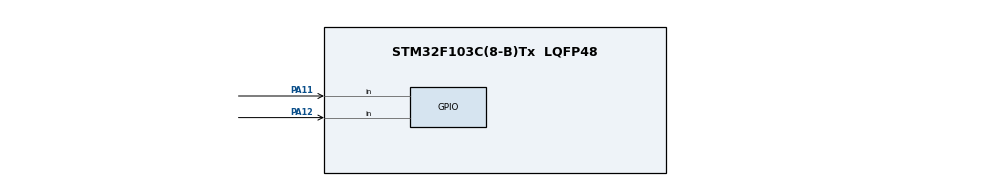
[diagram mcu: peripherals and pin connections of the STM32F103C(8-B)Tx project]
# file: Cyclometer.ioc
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Mcu.Family=STM32F1
Mcu.Name=STM32F103C(8-B)Tx
Mcu.Package=LQFP48
NVIC.PriorityGroup=NVIC_PRIORITYGROUP_4
PA10.Signal=USART1_RX
PA11.GPIO_PuPd=GPIO_PULLUP
PA11.Signal=GPIO_Input
PA12.GPIO_PuPd=GPIO_PULLUP
PA12.Signal=GPIO_Input
PA9.Signal=USART1_TX
ProjectManager.HeapSize=0x200
ProjectManager.StackSize=0x400
ProjectManager.TargetToolchain=MDK-ARM V5
RCC.APB1Freq_Value=8000000
RCC.APB2Freq_Value=8000000
TIM3.Period=199
TIM3.Prescaler=8000
VP_SYS_VS_ND.Mode=No_Debug
VP_TIM3_VS_ClockSourceINT.Mode=Internal
board=custom

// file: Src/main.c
/* USER CODE BEGIN Header */
/**
  ******************************************************************************
  * @file           : main.c
  * @brief          : Main program body
  ******************************************************************************
  * @attention
  *
  * <h2><center>&copy; Copyright (c) 2019 STMicroelectronics.
  * All rights reserved.</center></h2>
  *
  * This software component is licensed by ST under BSD 3-Clause license,
  * the "License"; You may not use this file except in compliance with the
  * License. You may obtain a copy of the License at:
  *                        opensource.org/licenses/BSD-3-Clause
  *
  ******************************************************************************
  */
/* USER CODE END Header */

#include "main.h"

TIM_HandleTypeDef htim3;

void SystemClock_Config(void);
static void MX_GPIO_Init(void);
static void MX_TIM3_Init(void);

/* USER CODE BEGIN 0 */
void UART_Init(UART_HandleTypeDef UartHandle);
/* USER CODE END 0 */

int main(void)
{

  /* MCU Configuration--------------------------------------------------------*/

  /* Reset of all peripherals, Initializes the Flash interface and the Systick. */
  HAL_Init();

  /* Configure the system clock */
  SystemClock_Config();

  /* Initialize all configured peripherals */
  MX_GPIO_Init();
  MX_TIM3_Init();
  /* USER CODE BEGIN 2 */
	UART_HandleTypeDef UartHandle;
	UART_Init(UartHandle);
  /* USER CODE END 2 */

  /* Infinite loop */
  while (1)
  {

    /* USER CODE BEGIN 3 */
		HAL_UART_Transmit(&UartHandle, (uint8_t*)"Hello, World!\r\n", 15, 100);
		HAL_Delay(100);
  }
  /* USER CODE END 3 */
}

void SystemClock_Config(void)
{
  RCC_OscInitTypeDef RCC_OscInitStruct = {0};
  RCC_ClkInitTypeDef RCC_ClkInitStruct = {0};

  /** Initializes the CPU, AHB and APB busses clocks
  */
  RCC_OscInitStruct.OscillatorType = RCC_OSCILLATORTYPE_HSI;
  RCC_OscInitStruct.HSIState = RCC_HSI_ON;
  RCC_OscInitStruct.HSICalibrationValue = RCC_HSICALIBRATION_DEFAULT;
  RCC_OscInitStruct.PLL.PLLState = RCC_PLL_NONE;
  if (HAL_RCC_OscConfig(&RCC_OscInitStruct) != HAL_OK)
  {
    Error_Handler();
  }
  /** Initializes the CPU, AHB and APB busses clocks
  */
  RCC_ClkInitStruct.ClockType = RCC_CLOCKTYPE_HCLK|RCC_CLOCKTYPE_SYSCLK
                              |RCC_CLOCKTYPE_PCLK1|RCC_CLOCKTYPE_PCLK2;
  RCC_ClkInitStruct.SYSCLKSource = RCC_SYSCLKSOURCE_HSI;
  RCC_ClkInitStruct.AHBCLKDivider = RCC_SYSCLK_DIV1;
  RCC_ClkInitStruct.APB1CLKDivider = RCC_HCLK_DIV1;
  RCC_ClkInitStruct.APB2CLKDivider = RCC_HCLK_DIV1;

  if (HAL_RCC_ClockConfig(&RCC_ClkInitStruct, FLASH_LATENCY_0) != HAL_OK)
  {
    Error_Handler();
  }
}

static void MX_TIM3_Init(void)
{

  TIM_ClockConfigTypeDef sClockSourceConfig = {0};
  TIM_MasterConfigTypeDef sMasterConfig = {0};

  htim3.Instance = TIM3;
  htim3.Init.Prescaler = 8000;
  htim3.Init.CounterMode = TIM_COUNTERMODE_UP;
  htim3.Init.Period = 199;
  htim3.Init.ClockDivision = TIM_CLOCKDIVISION_DIV1;
  htim3.Init.AutoReloadPreload = TIM_AUTORELOAD_PRELOAD_DISABLE;
  if (HAL_TIM_Base_Init(&htim3) != HAL_OK)
  {
    Error_Handler();
  }
  sClockSourceConfig.ClockSource = TIM_CLOCKSOURCE_INTERNAL;
  if (HAL_TIM_ConfigClockSource(&htim3, &sClockSourceConfig) != HAL_OK)
  {
    Error_Handler();
  }
  sMasterConfig.MasterOutputTrigger = TIM_TRGO_RESET;
  sMasterConfig.MasterSlaveMode = TIM_MASTERSLAVEMODE_DISABLE;
  if (HAL_TIMEx_MasterConfigSynchronization(&htim3, &sMasterConfig) != HAL_OK)
  {
    Error_Handler();
  }

}

static void MX_GPIO_Init(void)
{
  GPIO_InitTypeDef GPIO_InitStruct = {0};

  /* GPIO Ports Clock Enable */
  __HAL_RCC_GPIOA_CLK_ENABLE();

  /*Configure GPIO pin : PA9 */
  GPIO_InitStruct.Pin = GPIO_PIN_9;
  GPIO_InitStruct.Mode = GPIO_MODE_AF_PP;
  GPIO_InitStruct.Speed = GPIO_SPEED_FREQ_HIGH;
  HAL_GPIO_Init(GPIOA, &GPIO_InitStruct);

  /*Configure GPIO pin : PA10 */
  GPIO_InitStruct.Pin = GPIO_PIN_10;
  GPIO_InitStruct.Mode = GPIO_MODE_INPUT;
  GPIO_InitStruct.Pull = GPIO_NOPULL;
  HAL_GPIO_Init(GPIOA, &GPIO_InitStruct);

  /*Configure GPIO pins : PA11 PA12 */
  GPIO_InitStruct.Pin = GPIO_PIN_11|GPIO_PIN_12;
  GPIO_InitStruct.Mode = GPIO_MODE_INPUT;
  GPIO_InitStruct.Pull = GPIO_PULLUP;
  HAL_GPIO_Init(GPIOA, &GPIO_InitStruct);

}

/* USER CODE BEGIN 4 */
/**
  * @brief UART Initialization Function
  * @param UART Handle
  * @retval None
  */
void UART_Init(UART_HandleTypeDef UartHandle)
{
	UartHandle.Instance = USART1;
	UartHandle.Init.BaudRate = 9600;
	UartHandle.Init.WordLength = UART_WORDLENGTH_8B;
	UartHandle.Init.StopBits = UART_STOPBITS_1;
	UartHandle.Init.Parity = UART_PARITY_NONE;
	UartHandle.Init.HwFlowCtl = UART_HWCONTROL_NONE;
	UartHandle.Init.Mode = UART_MODE_TX_RX;
	UartHandle.Init.OverSampling = UART_OVERSAMPLING_16;

	HAL_UART_Init(&UartHandle);
}
/* USER CODE END 4 */

void Error_Handler(void)
{
}

/************************ (C) COPYRIGHT STMicroelectronics *****END OF FILE****/
